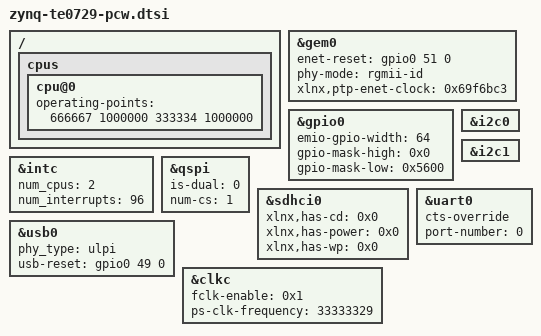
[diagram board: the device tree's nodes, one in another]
/*
 * CAUTION: This file is automatically generated by Xilinx.
 * Version: XSCT
 * Today is: Wed Jun 17 08:33:22 2026
 */


/ {
        cpus {
                cpu@0 {
                        operating-points = <666667 1000000 333334 1000000>;
                };
        };
};
&gem0 {
        enet-reset = <&gpio0 51 0>;
        phy-mode = "rgmii-id";
        status = "okay";
        xlnx,ptp-enet-clock = <0x69f6bc3>;
};
&gpio0 {
        emio-gpio-width = <64>;
        gpio-mask-high = <0x0>;
        gpio-mask-low = <0x5600>;
};
&i2c0 {
        status = "okay";
};
&i2c1 {
        status = "okay";
};
&intc {
        num_cpus = <2>;
        num_interrupts = <96>;
};
&qspi {
        is-dual = <0>;
        num-cs = <1>;
        status = "okay";
};
&sdhci0 {
        status = "okay";
        xlnx,has-cd = <0x0>;
        xlnx,has-power = <0x0>;
        xlnx,has-wp = <0x0>;
};
&uart0 {
        cts-override ;
        device_type = "serial";
        port-number = <0>;
        status = "okay";
};
&usb0 {
        phy_type = "ulpi";
        status = "okay";
        usb-reset = <&gpio0 49 0>;
};
&clkc {
        fclk-enable = <0x1>;
        ps-clk-frequency = <33333329>;
};
